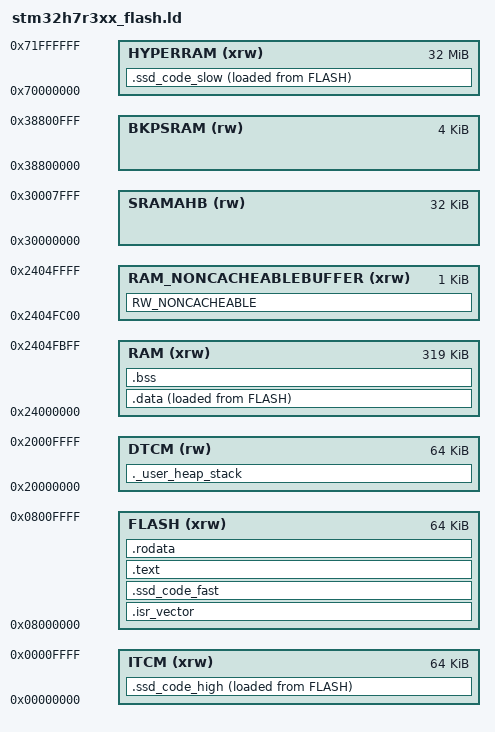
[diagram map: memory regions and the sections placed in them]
/*
******************************************************************************
**
** @file        : LinkerScript.ld
**
** @author      : Auto-generated by STM32CubeIDE
**
** @brief       : Linker script for STM32H7R3xx Device from STM32H7RS series
**                      64Kbytes FLASH
**                      456Kbytes RAM
**
**                Set heap size, stack size and stack location according
**                to application requirements.
**
**                Set memory bank area and size if external memory is used
**
**  Target      : STMicroelectronics STM32
**
**  Distribution: The file is distributed as is, without any warranty
**                of any kind.
**
******************************************************************************
** @attention
**
** Copyright (c) 2023 STMicroelectronics.
** All rights reserved.
**
** This software is licensed under terms that can be found in the LICENSE file
** in the root directory of this software component.
** If no LICENSE file comes with this software, it is provided AS-IS.
**
******************************************************************************
*/

/* Entry Point */
ENTRY(Reset_Handler)

/* Highest address of the user mode stack */
_estack = ORIGIN(DTCM) + LENGTH(DTCM); /* end of "DTCM" Ram type memory */

_Min_Heap_Size = 0x200; /* required amount of heap */
_Min_Stack_Size = 0x400; /* required amount of stack */

__FLASH_BEGIN  = 0x08000000;
__FLASH_SIZE   = 0x00010000;


__RAM_BEGIN    = 0x24000000;
__RAM_SIZE     = 0x4FC00;
__RAM_NONCACHEABLEBUFFER_SIZE = 0x400;

/* Memories definition */
MEMORY
{
  RAM       (xrw) : ORIGIN = __RAM_BEGIN,    LENGTH = __RAM_SIZE
  RAM_NONCACHEABLEBUFFER (xrw) : ORIGIN = __RAM_BEGIN + __RAM_SIZE,  LENGTH = __RAM_NONCACHEABLEBUFFER_SIZE

  ITCM      (xrw) : ORIGIN = 0x00000000,    LENGTH = 0x00010000
  DTCM       (rw) : ORIGIN = 0x20000000,    LENGTH = 0x00010000
  SRAMAHB   (rw)  : ORIGIN = 0x30000000,  LENGTH = 0x00008000
  BKPSRAM   (rw)  : ORIGIN = 0x38800000,  LENGTH = 0x00001000

  FLASH     (xrw) : ORIGIN = __FLASH_BEGIN, LENGTH = __FLASH_SIZE
  /* XSPI2 HyperRAM 映射窗口；低速代码在运行时从 FLASH 搬运到此处。 */
  HYPERRAM  (xrw) : ORIGIN = 0x70000000, LENGTH = 32M
}

/* Sections */
SECTIONS
{
  /* The startup code into "FLASH" Rom type memory */
  .isr_vector :
  {
    . = ALIGN(4);
    KEEP(*(.isr_vector)) /* Startup code */
    . = ALIGN(4);
  } >FLASH

  /* 高速代码：VMA 在 ITCM，LMA 在内部 Flash，由启动文件复制。 */
  .ssd_code_high :
  {
    . = ALIGN(4);
    __ssd_code_high_start = .;
    KEEP(*(.ssd_code_high))
    KEEP(*(.ssd_code_high.*))
    . = ALIGN(4);
    __ssd_code_high_end = .;
  } >ITCM AT>FLASH
  __ssd_code_high_load_start = LOADADDR(.ssd_code_high);

  /* 快速代码保留在内部 Flash，直接执行。 */
  .ssd_code_fast :
  {
    . = ALIGN(4);
    KEEP(*(.ssd_code_fast))
    KEEP(*(.ssd_code_fast.*))
    . = ALIGN(4);
  } >FLASH

  /* 低速代码：VMA 在 HyperRAM，LMA 在 Flash；不可在 HyperRAM 初始化前调用。 */
  .ssd_code_slow :
  {
    . = ALIGN(4);
    __ssd_code_slow_start = .;
    KEEP(*(.ssd_code_slow))
    KEEP(*(.ssd_code_slow.*))
    . = ALIGN(4);
    __ssd_code_slow_end = .;
  } >HYPERRAM AT>FLASH
  __ssd_code_slow_load_start = LOADADDR(.ssd_code_slow);

  /* The program code and other data into "FLASH" Rom type memory */
  .text :
  {
    . = ALIGN(4);
    *(.text)           /* .text sections (code) */
    *(.text*)          /* .text* sections (code) */
    *(.glue_7)         /* glue arm to thumb code */
    *(.glue_7t)        /* glue thumb to arm code */

    KEEP (*(.init))
    KEEP (*(.fini))

    . = ALIGN(4);
    _etext = .;        /* define a global symbols at end of code */
  } >FLASH

  /* Constant data into "FLASH" Rom type memory */
  .rodata :
  {
    . = ALIGN(4);
    *(.rodata)         /* .rodata sections (constants, strings, etc.) */
    *(.rodata*)        /* .rodata* sections (constants, strings, etc.) */
    . = ALIGN(4);
  } >FLASH


  /* Used by the startup to initialize data */
  _sidata = LOADADDR(.data);

  /* Initialized data sections into "RAM" Ram type memory */
  .data :
  {
    . = ALIGN(4);
    _sdata = .;        /* create a global symbol at data start */
    *(.data)           /* .data sections */
    *(.data*)          /* .data* sections */
    *(.RamFunc)        /* .RamFunc sections */
    *(.RamFunc*)       /* .RamFunc* sections */

    . = ALIGN(4);
    _edata = .;        /* define a global symbol at data end */

  } >RAM AT> FLASH

  /* Uninitialized data section into "RAM" Ram type memory */
  . = ALIGN(4);
  .bss :
  {
    /* This is used by the startup in order to initialize the .bss section */
    _sbss = .;         /* define a global symbol at bss start */
    __bss_start__ = _sbss;
    *(.bss)
    *(.bss*)
    *(COMMON)

    . = ALIGN(4);
    _ebss = .;         /* define a global symbol at bss end */
    __bss_end__ = _ebss;
  } >RAM

  RW_NONCACHEABLE (NOLOAD):
  {
    __NONCACHEABLEBUFFER_BEGIN = .;/* create symbol for start of section */
    KEEP(*(noncacheable_buffer))
    __NONCACHEABLEBUFFER_END = .;  /* create symbol for start of section */
  } > RAM_NONCACHEABLEBUFFER

  /* User_heap_stack section, used to check that there is enough "DTCM" Ram  type memory left */
  ._user_heap_stack :
  {
    . = ALIGN(8);
    PROVIDE ( end = . );
    PROVIDE ( _end = . );
    . = . + _Min_Heap_Size;
    . = . + _Min_Stack_Size;
    . = ALIGN(8);
  } >DTCM

  /* Remove information from the compiler libraries */
  /DISCARD/ :
  {
    libc.a ( * )
    libm.a ( * )
    libgcc.a ( * )
    /* 本工程为纯 C 裸机固件，不保留 C++ 异常/栈展开元数据。 */
    *(.eh_frame*)
    *(.ARM.extab*)
    *(.ARM.exidx*)
  }

  .ARM.attributes 0 : { *(.ARM.attributes) }
}
